# ECM3531 register map
Vendor: EtaCompute; Series: ECM35xx; File version: 1.0.0
CPU: CM3 r1p1, little endian, MPU, no FPU, 3 interrupt priority bits
Registers are 32-bit, read-write, reset 0x0 unless marked. A register's access mark holds for its fields unless they carry their own. Offsets are from the block's base; [hi:lo] are bit positions; {n}, {i} and the like mark numbered series.

## FLASH_CTLR — The flash controller module provides capabilities to erase and program the embedded flash memory storage.
Base 0xE0080000
0x00 STATUS — Status bits for the Flash Control Module.
  [0] READY ro — This bit indicates that the controller is ready to receive write data or that a timer count has reached 0.
    1=READY (The flash controller is ready to receive write data and there is no active timer countdown.); 0=NOT_READY (The flash controller is not ready to receive data or that the timer has not completed a count to 0.)
0x04 CONTROLEN — Enable/Disable the flash controller to erase or program the embedded flash.
  [31:0] KEY — Enable the flash controller to drive the flash instance signals by writing the value 0x5c3a1ec9 to this location. A write of any other value will revert control of the flash signals to the M3.
0x10 CONTROL0 — Control bits for the Flash Control Module. This register controls the status power states and signal ownership control.
  [0] LVEN — Indicates to the Flash Memory whether the voltage range is low (0.81 - 1.08V) or high (1.08 - 1.32V).
    1=LOWV (The flash is operating in the low voltages range (0.81 - 1.08V).); 0=HIGHV (The flash is operating in the high voltages range (1.08 - 1.32V).)
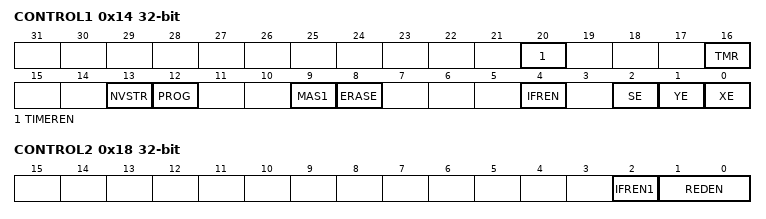
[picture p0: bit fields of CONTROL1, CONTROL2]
0x14 CONTROL1 — Control bits for the Flash Control Module. This is the primary register used to control signals for program and erase operations.
  [20] TIMEREN wo — When set to a 1, the Flash Controller Timer will begin counting down from the value written to the Count Register to 0 at 1uS intervals.
  [16] TMR — This bit controls the TMR pin of the embedded flash. It is only used during the Erase Reference Cell operation and should be set to 1 at all other times.
  [13] NVSTR — This bit controls the NVSTR pin of the embedded flash. It is set or cleared as required for a particular operation.
  [12] PROG — This bit controls the PROG pin of the embedded flash. It is set or cleared as required for a particular operation.
  [9] MAS1 — This bit controls the MAS1 pin of the embedded flash. It is set or cleared as required for a particular operation.
  [8] ERASE — This bit controls the ERASE pin of the embedded flash. It is set or cleared as required for a particular operation.
  [4] IFREN — This bit controls the IFREN pin of the embedded flash. It is set or cleared as required for a particular operation.
  [2] SE — This bit controls the SE pin of the embedded flash. It is set or cleared as required for a particular operation.
  [1] YE — This bit controls the YE pin of the embedded flash. It is set or cleared as required for a particular operation.
  [0] XE — This bit controls the XE pin of the embedded flash. It is set or cleared as required for a particular operation.
0x18 CONTROL2 — Control bits for the Flash Redundancy Modes.
  [2] IFREN1 — This bit enables access to the Flash's Redundant Information Page. NOT USED CURRENTLY
    1=ENABLE (User can access data in the redundant information page.); 0=DISABLE (User can perform normal memory accesses.)
  [1:0] REDEN — This bit enables access to the Flash's Redundant Data Pages. The flash instance supports 2 redundancy pages to improve yield during manufacturing. If utilized, when the user attempts to access a bad page, the REDEN[] bit can be set to allow use of the redundant page. Only one of the 2 bits can be set, the value represents one of two possible redundant pages. NOT CURRENTLY USED
    0=NORMAL (The regular pages of the array are used for accesses.); 1=PAGE0 (Redundant page0 is accessed rather than the normal page for this address.); 2=PAGE1 (Redundant page1 is accessed rather than the normal page for this address.)
0x20 TIMER — 20-bit count value which is used by the Flash Controller Timer. The timer counts at 1uS intervals, and the 20b value give us up to 1S of time.
  [19:0] COUNT — 20-bit count value which is loaded into the controller's timer and then counts to 0 at 1uS increments. The value written to this register is retained and can be reused as needed.
0x30 ADDR — Address of the Flash Memory to write data.
  [31:0] ADDR — The address of the Flash Memory to use for erase, program, and read operations. This is a byte address, although the flash is only accessible at 32b word boundaries.
{0x40+4i} DATA{i} (i=0..3) — 32-bits of data[{32i+31}:{32i}] to be written to or read from the Flash memory.
  [31:0] DATA

## DSPCTRL_M3 — These registers control the DSP complex.
Base 0x40800000
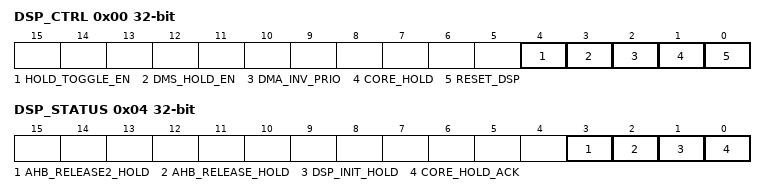
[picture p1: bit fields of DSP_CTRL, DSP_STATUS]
0x00 DSP_CTRL — DSP Control register
  [4] HOLD_TOGGLE_EN — This is a purely debug feature that effectively emulates a very fast series of writes to RELEASE_HOLD_PULSE. So by setting this field (and DSP_CTRL.CORE_HOLD), the DSP will go approximately 1/3 slower and be affected by a series of holds. Useful for testing unexpected hold cases.
  [3] DMS_HOLD_EN — From NXP doc: Controls the function of the core_hold input. When dms_hold_en is high, a high on core_hold puts the entire CoolFlux DSP into the hold state (same as io_hold). When dms_hold_en is low, a high on core_hold puts the entire CoolFlux DSP except the DMS block into the hold state; the DMS block remains John's translation: setting dms_hold_en and core_hold stops everything and would likely PREVENT PMEM, XMEM, YMEM access.
  [2] DMA_INV_PRIO — If set to 1, the DMA and AHB have highest priority access to the PMEM, XMEM and YMEM. If set to 0, the DSP Core typically has priority (note the DSP has a timeout capability that can override this setting).
  [1] CORE_HOLD — Setting this bit places the DSP in hold. To confirm it is in hold, look at the core_hold_ack bit in the dsp_status. dma_hold_en affects how this bit is interpreted. Theoretically, setting this bit and then clearing it should allow the DSP to pause and then restart.
  [0] RESET_DSP — Setting this bit resets most of the DSP Core and holds it in a reset state. When this is high and the DSP complex is out of reset, the AHB has access to PMEM, XMEM and YMEM without the DSP attempting to access those memories.
0x04 DSP_STATUS
  [3] AHB_RELEASE2_HOLD ro — Live value of toggle hold enabled by DSP_CTRL.HOLD_TOGGLE_EN. When this bit is one, the core is in HOLD, while zero the core is running.
  [2] AHB_RELEASE_HOLD ro — Live value of core_hold_ack from DSP Core. When it is one, the core is safely in HOLD.
  [1] DSP_INIT_HOLD — This bit is set by the DSP when it wants to initiate a hold (dsp_hold) or by DSP debug logic when it detects a warning in AHB window control register dsp_status and control_status.warn_to_hold is set. It is cleared by writing a 1 to this location, presumably after debugging is complete.
  [0] CORE_HOLD_ACK ro — Live value of core_hold_ack from DSP Core. When it is one, the core is safely in HOLD.
0x08 RELEASE_HOLD_PULSE — This debug register allows for single instruction stepping from the outside for debug purposes. To use it, first assert core_hold (DSP_CTRL.CORE_HOLD). Then write any value to this register, which will cause the core_hold to be temporarily driven low. Note that the logic waits for core_hold_ack to deassert before it reasserts core_hold, which should allow for one instruction to complete.
  [31:0] DATA — Any write will pulse HOLD low.
0x20 DMA_SRCRDY_12 — CSR bit for DSP DMA engine. Accessible from AHB and IOBUS and usable by DMA engine.
  [0] READY — Write a 1 to mark this as ready.
0x24 DMA_SRCRDY_13 — CSR bit for DSP DMA engine. Accessible from AHB and IOBUS and usable by DMA engine.
  [0] READY — Write a 1 to mark this as ready.
0x28 DMA_SRCRDY_14 — CSR bit for DSP DMA engine. Accessible from AHB and IOBUS and usable by DMA engine.
  [0] READY — Write a 1 to mark this as ready.
0x2C DMA_SRCRDY_15 — CSR bit for DSP DMA engine. Accessible from AHB and IOBUS and usable by DMA engine.
  [0] READY — Write a 1 to mark this as ready.
{0x0+4i} DMA_DSTRDY_{i} (i=12..15) — CSR bit for DSP DMA engine. Accessible from AHB and IOBUS and usable by DMA engine.
  [0] READY — Write a 1 to mark this as ready.
